# RA2A1 register map
Vendor: Renesas Electronics Corporation; Series: RA2; File version: 1.1
CPU: other r1p0, little endian, MPU, no FPU, VTOR, 2 interrupt priority bits
Registers are 8-bit, read-write, reset 0x0 unless marked. A register's access mark holds for its fields unless they carry their own. Offsets are from the block's base; [hi:lo] are bit positions.

## ACMPHS0 — High-Speed Analog Comparator 0
Base 0x40085000
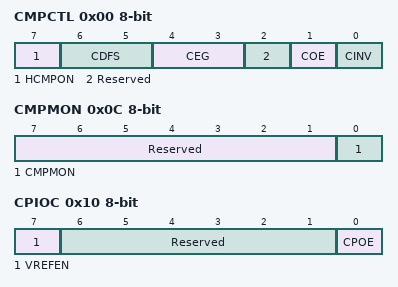
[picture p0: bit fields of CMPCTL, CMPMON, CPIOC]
0x00 CMPCTL — Comparator Control Register
  [7] HCMPON — Comparator operation control
    0=Operation stopped (the comparator outputs a low-level signal); 1=Operation enabled (input to the comparator pins is enabled
  [6:5] CDFS — Noise filter selection
    0=Noise filter not used; 1=Noise filter sampling frequency is 2^3/PCLKB; 2=Noise filter sampling frequency is 2^4/PCLKB; 3=Noise filter sampling frequency is 2^5/PCLKB
  [4:3] CEG — Selection of valid edge (Edge selector)
    0=No edge selection; 1=Rising edge selection; 2=Falling edge selection; 3=Both-edge selection
  [2] Reserved — This bit is read as 0. The write value should be 0.
  [1] COE — Comparator output enable
    0=Comparator output disabled (the output signal is low level); 1=Comparator output enabled
  [0] CINV — Comparator output polarity selection
    0=Comparator output not inverted; 1=Comparator output inverted
0x04 CMPSEL0 — Comparator Input Select Register
  [2:0] CMPSEL — Comparator input selection
    0=No input; 1=IVCMP0 selected; 2=IVCMP1 selected; 4=IVCMP2 selected; other=others (Setting prohibited)
0x08 CMPSEL1 — Comparator Reference Voltage Select Register
  [5:0] CRVS — Reference voltage selection
    0=No reference voltage; 1=IVREF0 selected; 2=IVREF1 selected; 4=IVREF2 selected; 8=IVREF3 selected; 16=IVREF4 selected; 32=IVREF5 selected; other=others (Setting prohibited)
0x0C CMPMON ro — Comparator Output Monitor Register
  [7:1] Reserved — These bits are read as 0000000.
  [0] CMPMON — Comparator output monitor
    0=Comparator output Low; 1=Comparator output High
0x10 CPIOC — Comparator Output Control Register
  [7] VREFEN — Internal Vref enable
    0=Internal Vref disable; 1=Internal Vref enable
  [6:1] Reserved — These bits are read as 000000. The write value should be 000000.
  [0] CPOE — Comparator output selection
    0=VCOUT pin output of the comparator is disabled (the output signal is low level); 1=VCOUT pin output of the comparator is enabled

## TSN — Temperature Sensor
Base 0x407EC000
0x228 TSCDRL ro reset not defined — Temperature Sensor Calibration Data Register L
  [7:0] TSCDRL — The calibration data stores the lower 8 bits of the convertedvalue.
0x229 TSCDRH ro reset not defined — Temperature Sensor Calibration Data Register H
  [7:0] TSCDRH — The calibration data stores the higher 8 bits of the convertedvalue.

## DAC12 — 12-bit D/A converter
Base 0x4005E000
0x00 DADR0 16-bit — D/A Data Register 0
  [15:0] DADR — D/A Data RegisterNOTE: When DADPR.DPSEL = 0, the high-order 4 bits are fixed to 0: right justified format. When DADPR.DPSEL = 1, the low-order 4 bits are fixed to 0: left justified format.
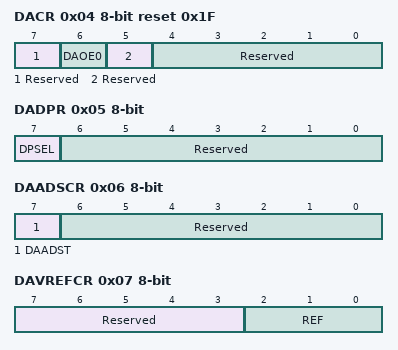
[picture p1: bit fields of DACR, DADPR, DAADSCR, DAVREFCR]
0x04 DACR reset 0x1F — D/A Control Register
  [7] Reserved — This bit is read as 0. The write value should be 0.
  [6] DAOE0 — D/A Output Enable 0
    0=Analog output of channel 0 (DA0) is disabled; 1=D/A conversion of channel 0 is enabled. Analog output of channel 0 (DA0) is enabled.
  [5] Reserved — This bit is read as 0. The write value should be 0.
  [4:0] Reserved — These bits are read as 11111. The write value should be 11111.
0x05 DADPR — DADR0 Format Select Register
  [7] DPSEL — DADRm Format Select
    0=Right justified format; 1=Left justified format
  [6:0] Reserved — These bits are read as 0000000. The write value should be 0000000.
0x06 DAADSCR — D/A-A/D Synchronous Start Control Register
  [7] DAADST — D/A-A/D Synchronous Conversion
    0=D/A converter operation does not synchronize with A/D converter operation (unit 1) (countermeasure against interference between D/A and A/D conversions is disabled); 1=D/A converter operation synchronizes with A/D converter operation (unit 1) (countermeasure against interference between D/A and A/D conversions is enabled)
  [6:0] Reserved — These bits are read as 0000000. The write value should be 0000000.
0x07 DAVREFCR — D/A VREF Control Register
  [7:3] Reserved — These bits are read as 00000. The write value should be 00000.
  [2:0] REF — D/A Reference Voltage Select
    0=Not selected; 1=AVCC0/AVSS0; 3=Internal reference voltage/AVSS0; 6=VREFH/VREFL; other=others (Setting prohibited)
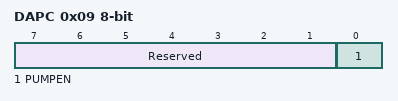
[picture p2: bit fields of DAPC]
0x09 DAPC — D/A Switch Charge Pump Control Register
  [7:1] Reserved — These bits are read as 0000000. The write value should be 0000000.
  [0] PUMPEN — Charge Pump Enable
    0=Charge pump disabled; 1=Charge pump enabled
